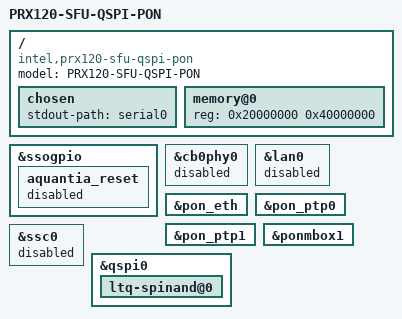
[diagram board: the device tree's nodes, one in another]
/dts-v1/;
#include "prx321-sfu-12.dtsi"

/ {
	model = "PRX120-SFU-QSPI-PON";
	compatible = "intel,prx120-sfu-qspi-pon", "intel,prx120-sfu", "intel,prx300";

	chosen {
		stdout-path = "serial0";
	};

	memory@0 {
		device_type = "memory";
		reg = <0x20000000 0x40000000>; /* 1024 MB */
	};
};

&ssogpio {

	aquantia_reset {
		status = "disabled";
	};
};

&cb0phy0 {
	status = "disabled";
};

&lan0 {
	status = "disabled";
};

&pon_eth {
	status = "okay";
};

&pon_ptp0 {
	status = "okay";
};

&pon_ptp1 {
	status = "okay";
};

&ponmbox1 {
	status = "okay";
};

&ssc0 {
	status = "disabled";
};

&qspi0 {
	status = "okay";
	ltq-spinand@0 {
		status = "okay";
	};
};

